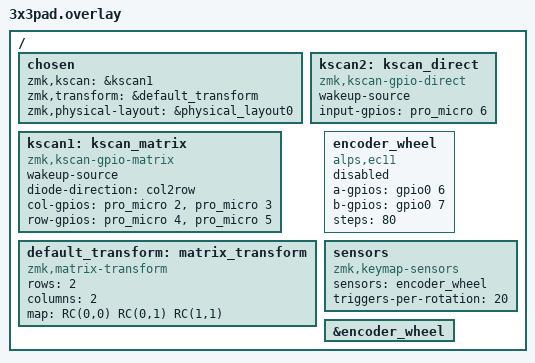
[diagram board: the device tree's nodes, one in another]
#include <dt-bindings/zmk/matrix_transform.h> // Put this with the other includes at the top of your overlay
#include <physical_layouts.dtsi>
#include "3x3pad-layouts.dtsi"

/ {
    chosen {
        zmk,kscan = &kscan1;
        zmk,transform = &default_transform;
        zmk,physical-layout = &physical_layout0;
    };

    kscan1: kscan_matrix {
        compatible = "zmk,kscan-gpio-matrix";
        wakeup-source;
        diode-direction = "col2row";
        wakeup-source;

        col-gpios
            = <&pro_micro 2 GPIO_ACTIVE_HIGH>
            , <&pro_micro 3 GPIO_ACTIVE_HIGH>
            ;

        row-gpios
            = <&pro_micro 4 (GPIO_ACTIVE_HIGH | GPIO_PULL_DOWN)>
            , <&pro_micro 5 (GPIO_ACTIVE_HIGH | GPIO_PULL_DOWN)>
            ;
    };

    kscan2: kscan_direct {
        compatible = "zmk,kscan-gpio-direct";
        wakeup-source;
        input-gpios
            = <&pro_micro 6 GPIO_ACTIVE_HIGH>
            ;
    };

    default_transform: matrix_transform {
        compatible = "zmk,matrix-transform";
        rows = <2>;
        columns = <2>;
        map = <
            RC(0,0) RC(0,1)
            RC(1,1)
            >;
    };

     encoder_wheel: encoder_wheel {
        compatible = "alps,ec11";
        /* Replace PIN_A and PIN_B with your actual pin numbers.
           Here, we assume the encoder A is on pin 12 and B is on pin 13 of gpio0.
           Adjust the GPIO flags (e.g., GPIO_ACTIVE_HIGH | GPIO_PULL_UP) as needed. */
        a-gpios = <&gpio0 6 (GPIO_ACTIVE_HIGH | GPIO_PULL_UP)>;
        b-gpios = <&gpio0 7 (GPIO_ACTIVE_HIGH | GPIO_PULL_UP)>;
        steps = <80>;  /* Number of pulses per rotation from the datasheet */
        status = "disabled";  /* Initially disabled */
    };

    sensors: sensors {
        compatible = "zmk,keymap-sensors";
        sensors = <&encoder_wheel>;
        triggers-per-rotation = <20>;
    };

    &encoder_wheel {
        status = "okay";
    }

};
